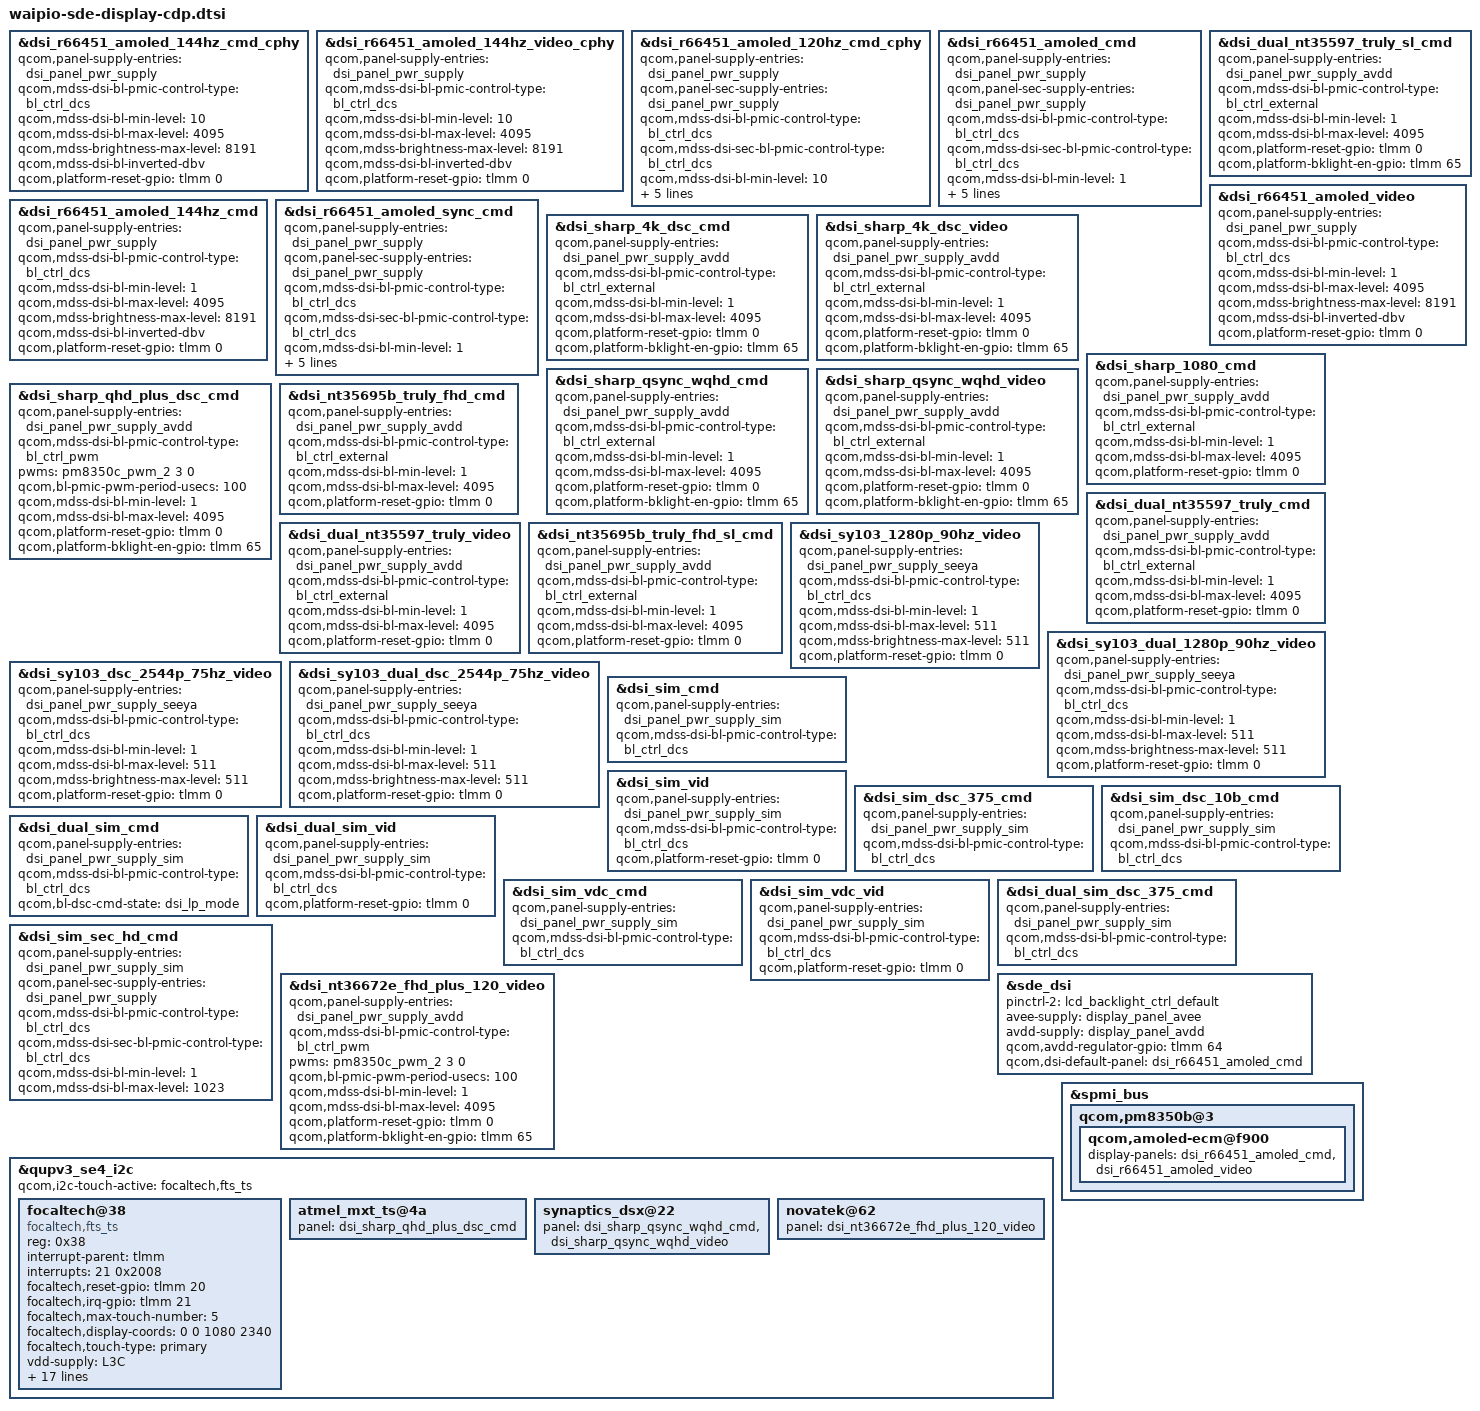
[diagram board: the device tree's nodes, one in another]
// SPDX-License-Identifier: BSD-3-Clause
/*
 * Copyright (c) Qualcomm Technologies, Inc. and/or its subsidiaries.
 */

#include "waipio-sde-display.dtsi"

&dsi_r66451_amoled_144hz_cmd_cphy {
	qcom,panel-supply-entries = <&dsi_panel_pwr_supply>;
	qcom,mdss-dsi-bl-pmic-control-type = "bl_ctrl_dcs";
	qcom,mdss-dsi-bl-min-level = <10>;
	qcom,mdss-dsi-bl-max-level = <4095>;
	qcom,mdss-brightness-max-level = <8191>;
	qcom,mdss-dsi-bl-inverted-dbv;
	qcom,platform-reset-gpio = <&tlmm 0 0>;
};

&dsi_r66451_amoled_144hz_video_cphy {
	qcom,panel-supply-entries = <&dsi_panel_pwr_supply>;
	qcom,mdss-dsi-bl-pmic-control-type = "bl_ctrl_dcs";
	qcom,mdss-dsi-bl-min-level = <10>;
	qcom,mdss-dsi-bl-max-level = <4095>;
	qcom,mdss-brightness-max-level = <8191>;
	qcom,mdss-dsi-bl-inverted-dbv;
	qcom,platform-reset-gpio = <&tlmm 0 0>;
};

&dsi_r66451_amoled_120hz_cmd_cphy {
	qcom,panel-supply-entries = <&dsi_panel_pwr_supply>;
	qcom,panel-sec-supply-entries = <&dsi_panel_pwr_supply>;
	qcom,mdss-dsi-bl-pmic-control-type = "bl_ctrl_dcs";
	qcom,mdss-dsi-sec-bl-pmic-control-type = "bl_ctrl_dcs";
	qcom,mdss-dsi-bl-min-level = <10>;
	qcom,mdss-dsi-bl-max-level = <4095>;
	qcom,mdss-brightness-max-level = <8191>;
	qcom,mdss-dsi-bl-inverted-dbv;
	qcom,platform-reset-gpio = <&tlmm 0 0>;
	qcom,platform-sec-reset-gpio = <&tlmm 4 0>;
};

&dsi_r66451_amoled_cmd {
	qcom,panel-supply-entries = <&dsi_panel_pwr_supply>;
	qcom,panel-sec-supply-entries = <&dsi_panel_pwr_supply>;
	qcom,mdss-dsi-bl-pmic-control-type = "bl_ctrl_dcs";
	qcom,mdss-dsi-sec-bl-pmic-control-type = "bl_ctrl_dcs";
	qcom,mdss-dsi-bl-min-level = <1>;
	qcom,mdss-dsi-bl-max-level = <4095>;
	qcom,mdss-brightness-max-level = <8191>;
	qcom,mdss-dsi-bl-inverted-dbv;
	qcom,platform-reset-gpio = <&tlmm 0 0>;
	qcom,platform-sec-reset-gpio = <&tlmm 4 0>;
};

&dsi_dual_nt35597_truly_sl_cmd {
	qcom,panel-supply-entries = <&dsi_panel_pwr_supply_avdd>;
	qcom,mdss-dsi-bl-pmic-control-type = "bl_ctrl_external";
	qcom,mdss-dsi-bl-min-level = <1>;
	qcom,mdss-dsi-bl-max-level = <4095>;
	qcom,platform-reset-gpio = <&tlmm 0 0>;
	qcom,platform-bklight-en-gpio = <&tlmm 65 0>;
};

&dsi_r66451_amoled_video {
	qcom,panel-supply-entries = <&dsi_panel_pwr_supply>;
	qcom,mdss-dsi-bl-pmic-control-type = "bl_ctrl_dcs";
	qcom,mdss-dsi-bl-min-level = <1>;
	qcom,mdss-dsi-bl-max-level = <4095>;
	qcom,mdss-brightness-max-level = <8191>;
	qcom,mdss-dsi-bl-inverted-dbv;
	qcom,platform-reset-gpio = <&tlmm 0 0>;
};

&dsi_r66451_amoled_144hz_cmd {
	qcom,panel-supply-entries = <&dsi_panel_pwr_supply>;
	qcom,mdss-dsi-bl-pmic-control-type = "bl_ctrl_dcs";
	qcom,mdss-dsi-bl-min-level = <1>;
	qcom,mdss-dsi-bl-max-level = <4095>;
	qcom,mdss-brightness-max-level = <8191>;
	qcom,mdss-dsi-bl-inverted-dbv;
	qcom,platform-reset-gpio = <&tlmm 0 0>;
};

&dsi_r66451_amoled_sync_cmd {
	qcom,panel-supply-entries = <&dsi_panel_pwr_supply>;
	qcom,panel-sec-supply-entries = <&dsi_panel_pwr_supply>;
	qcom,mdss-dsi-bl-pmic-control-type = "bl_ctrl_dcs";
	qcom,mdss-dsi-sec-bl-pmic-control-type = "bl_ctrl_dcs";
	qcom,mdss-dsi-bl-min-level = <1>;
	qcom,mdss-dsi-bl-max-level = <4095>;
	qcom,mdss-brightness-max-level = <8191>;
	qcom,mdss-dsi-bl-inverted-dbv;
	qcom,platform-reset-gpio = <&tlmm 0 0>;
	qcom,platform-sec-reset-gpio = <&tlmm 4 0>;
};

&dsi_sharp_4k_dsc_cmd {
	qcom,panel-supply-entries = <&dsi_panel_pwr_supply_avdd>;
	qcom,mdss-dsi-bl-pmic-control-type = "bl_ctrl_external";
	qcom,mdss-dsi-bl-min-level = <1>;
	qcom,mdss-dsi-bl-max-level = <4095>;
	qcom,platform-reset-gpio = <&tlmm 0 0>;
	qcom,platform-bklight-en-gpio = <&tlmm 65 0>;
};

&dsi_sharp_4k_dsc_video {
	qcom,panel-supply-entries = <&dsi_panel_pwr_supply_avdd>;
	qcom,mdss-dsi-bl-pmic-control-type = "bl_ctrl_external";
	qcom,mdss-dsi-bl-min-level = <1>;
	qcom,mdss-dsi-bl-max-level = <4095>;
	qcom,platform-reset-gpio = <&tlmm 0 0>;
	qcom,platform-bklight-en-gpio = <&tlmm 65 0>;
};

&dsi_sharp_1080_cmd {
	qcom,panel-supply-entries = <&dsi_panel_pwr_supply_avdd>;
	qcom,mdss-dsi-bl-pmic-control-type = "bl_ctrl_external";
	qcom,mdss-dsi-bl-min-level = <1>;
	qcom,mdss-dsi-bl-max-level = <4095>;
	qcom,platform-reset-gpio = <&tlmm 0 0>;
};

&dsi_sharp_qsync_wqhd_cmd {
	qcom,panel-supply-entries = <&dsi_panel_pwr_supply_avdd>;
	qcom,mdss-dsi-bl-pmic-control-type = "bl_ctrl_external";
	qcom,mdss-dsi-bl-min-level = <1>;
	qcom,mdss-dsi-bl-max-level = <4095>;
	qcom,platform-reset-gpio = <&tlmm 0 0>;
	qcom,platform-bklight-en-gpio = <&tlmm 65 0>;
};

&dsi_sharp_qsync_wqhd_video {
	qcom,panel-supply-entries = <&dsi_panel_pwr_supply_avdd>;
	qcom,mdss-dsi-bl-pmic-control-type = "bl_ctrl_external";
	qcom,mdss-dsi-bl-min-level = <1>;
	qcom,mdss-dsi-bl-max-level = <4095>;
	qcom,platform-reset-gpio = <&tlmm 0 0>;
	qcom,platform-bklight-en-gpio = <&tlmm 65 0>;
};

&dsi_sharp_qhd_plus_dsc_cmd {
	qcom,panel-supply-entries = <&dsi_panel_pwr_supply_avdd>;
	qcom,mdss-dsi-bl-pmic-control-type = "bl_ctrl_pwm";
	pwms = <&pm8350c_pwm_2 3 0>;
	qcom,bl-pmic-pwm-period-usecs = <100>;
	qcom,mdss-dsi-bl-min-level = <1>;
	qcom,mdss-dsi-bl-max-level = <4095>;
	qcom,platform-reset-gpio = <&tlmm 0 0>;
	qcom,platform-bklight-en-gpio = <&tlmm 65 0>;
};

&dsi_nt35695b_truly_fhd_cmd {
	qcom,panel-supply-entries = <&dsi_panel_pwr_supply_avdd>;
	qcom,mdss-dsi-bl-pmic-control-type = "bl_ctrl_external";
	qcom,mdss-dsi-bl-min-level = <1>;
	qcom,mdss-dsi-bl-max-level = <4095>;
	qcom,platform-reset-gpio = <&tlmm 0 0>;
};

&dsi_dual_nt35597_truly_cmd {
	qcom,panel-supply-entries = <&dsi_panel_pwr_supply_avdd>;
	qcom,mdss-dsi-bl-pmic-control-type = "bl_ctrl_external";
	qcom,mdss-dsi-bl-min-level = <1>;
	qcom,mdss-dsi-bl-max-level = <4095>;
	qcom,platform-reset-gpio = <&tlmm 0 0>;
};

&dsi_dual_nt35597_truly_video {
	qcom,panel-supply-entries = <&dsi_panel_pwr_supply_avdd>;
	qcom,mdss-dsi-bl-pmic-control-type = "bl_ctrl_external";
	qcom,mdss-dsi-bl-min-level = <1>;
	qcom,mdss-dsi-bl-max-level = <4095>;
	qcom,platform-reset-gpio = <&tlmm 0 0>;
};

&dsi_nt35695b_truly_fhd_sl_cmd {
	qcom,panel-supply-entries = <&dsi_panel_pwr_supply_avdd>;
	qcom,mdss-dsi-bl-pmic-control-type = "bl_ctrl_external";
	qcom,mdss-dsi-bl-min-level = <1>;
	qcom,mdss-dsi-bl-max-level = <4095>;
	qcom,platform-reset-gpio = <&tlmm 0 0>;
};

&dsi_sy103_1280p_90hz_video {
	qcom,panel-supply-entries = <&dsi_panel_pwr_supply_seeya>;
	qcom,mdss-dsi-bl-pmic-control-type = "bl_ctrl_dcs";
	qcom,mdss-dsi-bl-min-level = <1>;
	qcom,mdss-dsi-bl-max-level = <511>;
	qcom,mdss-brightness-max-level = <511>;
	qcom,platform-reset-gpio = <&tlmm 0 0>;
};


&dsi_sy103_dual_1280p_90hz_video {
	qcom,panel-supply-entries = <&dsi_panel_pwr_supply_seeya>;
	qcom,mdss-dsi-bl-pmic-control-type = "bl_ctrl_dcs";
	qcom,mdss-dsi-bl-min-level = <1>;
	qcom,mdss-dsi-bl-max-level = <511>;
	qcom,mdss-brightness-max-level = <511>;
	qcom,platform-reset-gpio = <&tlmm 0 0>;
};

&dsi_sy103_dsc_2544p_75hz_video {
	qcom,panel-supply-entries = <&dsi_panel_pwr_supply_seeya>;
	qcom,mdss-dsi-bl-pmic-control-type = "bl_ctrl_dcs";
	qcom,mdss-dsi-bl-min-level = <1>;
	qcom,mdss-dsi-bl-max-level = <511>;
	qcom,mdss-brightness-max-level = <511>;
	qcom,platform-reset-gpio = <&tlmm 0 0>;
};

&dsi_sy103_dual_dsc_2544p_75hz_video {
	qcom,panel-supply-entries = <&dsi_panel_pwr_supply_seeya>;
	qcom,mdss-dsi-bl-pmic-control-type = "bl_ctrl_dcs";
	qcom,mdss-dsi-bl-min-level = <1>;
	qcom,mdss-dsi-bl-max-level = <511>;
	qcom,mdss-brightness-max-level = <511>;
	qcom,platform-reset-gpio = <&tlmm 0 0>;
};

&dsi_sim_cmd {
	qcom,panel-supply-entries = <&dsi_panel_pwr_supply_sim>;
	qcom,mdss-dsi-bl-pmic-control-type = "bl_ctrl_dcs";
};

&dsi_sim_vid {
	qcom,panel-supply-entries = <&dsi_panel_pwr_supply_sim>;
	qcom,mdss-dsi-bl-pmic-control-type = "bl_ctrl_dcs";
	qcom,platform-reset-gpio = <&tlmm 0 0>;
};

&dsi_sim_dsc_375_cmd {
	qcom,panel-supply-entries = <&dsi_panel_pwr_supply_sim>;
	qcom,mdss-dsi-bl-pmic-control-type = "bl_ctrl_dcs";
};

&dsi_sim_dsc_10b_cmd {
	qcom,panel-supply-entries = <&dsi_panel_pwr_supply_sim>;
	qcom,mdss-dsi-bl-pmic-control-type = "bl_ctrl_dcs";
};

&dsi_dual_sim_cmd {
	qcom,panel-supply-entries = <&dsi_panel_pwr_supply_sim>;
	qcom,mdss-dsi-bl-pmic-control-type = "bl_ctrl_dcs";
	qcom,bl-dsc-cmd-state = "dsi_lp_mode";
};

&dsi_dual_sim_vid {
	qcom,panel-supply-entries = <&dsi_panel_pwr_supply_sim>;
	qcom,mdss-dsi-bl-pmic-control-type = "bl_ctrl_dcs";
	qcom,platform-reset-gpio = <&tlmm 0 0>;
};

&dsi_sim_vdc_cmd {
	qcom,panel-supply-entries = <&dsi_panel_pwr_supply_sim>;
	qcom,mdss-dsi-bl-pmic-control-type = "bl_ctrl_dcs";
};

&dsi_sim_vdc_vid {
	qcom,panel-supply-entries = <&dsi_panel_pwr_supply_sim>;
	qcom,mdss-dsi-bl-pmic-control-type = "bl_ctrl_dcs";
	qcom,platform-reset-gpio = <&tlmm 0 0>;
};

&dsi_dual_sim_dsc_375_cmd {
	qcom,panel-supply-entries = <&dsi_panel_pwr_supply_sim>;
	qcom,mdss-dsi-bl-pmic-control-type = "bl_ctrl_dcs";
};

&dsi_sim_sec_hd_cmd {
	qcom,panel-supply-entries = <&dsi_panel_pwr_supply_sim>;
	qcom,panel-sec-supply-entries = <&dsi_panel_pwr_supply>;
	qcom,mdss-dsi-bl-pmic-control-type = "bl_ctrl_dcs";
	qcom,mdss-dsi-sec-bl-pmic-control-type = "bl_ctrl_dcs";
	qcom,mdss-dsi-bl-min-level = <1>;
	qcom,mdss-dsi-bl-max-level = <1023>;
};

&dsi_nt36672e_fhd_plus_120_video {
	qcom,panel-supply-entries = <&dsi_panel_pwr_supply_avdd>;
	qcom,mdss-dsi-bl-pmic-control-type = "bl_ctrl_pwm";
	pwms = <&pm8350c_pwm_2 3 0>;
	qcom,bl-pmic-pwm-period-usecs = <100>;
	qcom,mdss-dsi-bl-min-level = <1>;
	qcom,mdss-dsi-bl-max-level = <4095>;
	qcom,platform-reset-gpio = <&tlmm 0 0>;
	qcom,platform-bklight-en-gpio = <&tlmm 65 0>;
};

&sde_dsi {
	pinctrl-names = "panel_active", "panel_suspend", "pwm_pin";
	pinctrl-2 = <&lcd_backlight_ctrl_default>;
	avee-supply = <&display_panel_avee>;
	avdd-supply = <&display_panel_avdd>;
	qcom,avdd-regulator-gpio = <&tlmm 64 0>;
	qcom,dsi-default-panel = <&dsi_r66451_amoled_cmd>;
};

&qupv3_se4_i2c {
	qcom,i2c-touch-active = "focaltech,fts_ts";
	focaltech@38 {
		compatible = "focaltech,fts_ts";
		reg = <0x38>;
                interrupt-parent = <&tlmm>;
                interrupts = <21 0x2008>;
                focaltech,reset-gpio = <&tlmm 20 0x00>;
                focaltech,irq-gpio = <&tlmm 21 0x2008>;
                focaltech,max-touch-number = <5>;
                focaltech,display-coords = <0 0 1080 2340>;
                focaltech,touch-type = "primary";

                vdd-supply = <&L3C>;
                vcc_i2c-supply = <&L8C>;

                pinctrl-names = "pmx_ts_active", "pmx_ts_suspend","pmx_ts_release";
                pinctrl-0 = <&ts_active>;
                pinctrl-1 = <&ts_int_suspend &ts_reset_suspend>;
                pinctrl-2 = <&ts_release>;
                focaltech,trusted-touch-mode = "vm_mode";
                focaltech,touch-environment = "pvm";
                focaltech,trusted-touch-type = "primary";
                focaltech,trusted-touch-spi-irq = <754>;
                focaltech,trusted-touch-io-bases = <0x990000 0x910000>;
                focaltech,trusted-touch-io-sizes = <0x1000 0x4000>;
                focaltech,trusted-touch-vm-gpio-list = <&tlmm 16 0 &tlmm 17 0 &tlmm 18 0
                                                &tlmm 19 0 &tlmm 20 0 &tlmm 21 0x2008>;
		panel = <&dsi_r66451_amoled_cmd
			&dsi_r66451_amoled_video>;
	};

	atmel_mxt_ts@4a {
		panel = <&dsi_sharp_qhd_plus_dsc_cmd>;
	};

	synaptics_dsx@22 {
		panel = <&dsi_sharp_qsync_wqhd_cmd
			&dsi_sharp_qsync_wqhd_video>;
	};

	novatek@62 {
		panel = <&dsi_nt36672e_fhd_plus_120_video>;
	};
};

&spmi_bus {
	qcom,pm8350b@3 {
		qcom,amoled-ecm@f900 {
			display-panels = <&dsi_r66451_amoled_cmd
					&dsi_r66451_amoled_video>;
		};
	};
};
